# TC37XPD register map
Vendor: Infineon; Series: ATVMC; File version: 100
CPU: other r0p0, little endian, MPU, FPU, vendor SysTick, 4 interrupt priority bits
Registers are 32-bit, read-write, reset 0x0 unless marked. A register's access mark holds for its fields unless they carry their own. Offsets are from the block's base; [hi:lo] are bit positions; {n}, {i} and the like mark numbered series.

## PSI5S
Base 0xF0007000
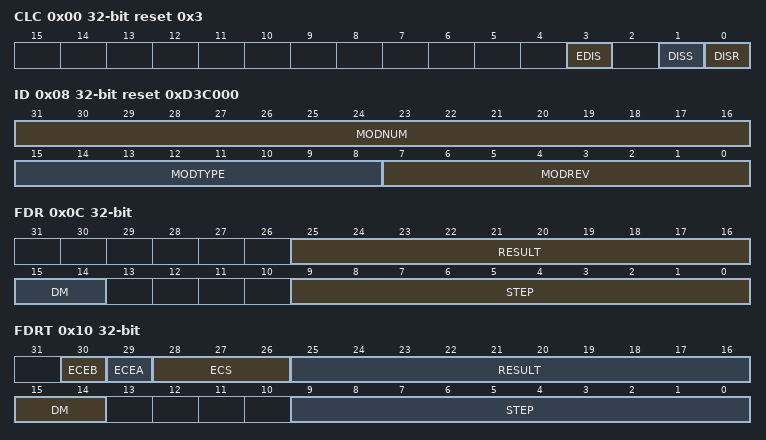
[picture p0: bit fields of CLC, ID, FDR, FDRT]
0x00 CLC access per field reset 0x3 — Clock Control Register resetvalue={Application Reset:0x3}
  [3] EDIS rw — External Sleep Mode Request Disable Bit EDIS. Used to control module s sleep mode. If this bit is cleared the kernel clocks f PSI5 S and the ASC clock f ASC are disabled during System Sleep Mode.
  [1] DISS ro — Module Disable Status Bit DISS. Bit indicates the current status of the module.
  [0] DISR rw — Module Disable Request Bit DISR. Used for enable disable control of the module. This bit disables the kernel clocks f PSI5 S and the ASC clock f ASC .
0x08 ID ro reset 0xD3C000 (reset mask 0xFFFFFF00) — Module Identification Register resetvalue={Application Reset:0x0D3C000}
  [31:16] MODNUM — Module Number Value MODNUM. This bit field defines the module identification number for the PSI5 S 00D3 H
  [15:8] MODTYPE — Module Type MODTYPE. This bit field defines the module as a 32 bit module C0 H
  [7:0] MODREV — Module Revision Number MODREV. This bit field defines the module revision number. The value of a module revision starts with 01 H first revision .
0x0C FDR access per field — PSI5 S Fractional Divider Register resetvalue={Application Reset:0x0}
  [25:16] RESULT ro — Result Value RESULT. Bit field for the addition result.
  [15:14] DM rw — Divider Mode DM. DM selects normal or fractional divider mode.
  [9:0] STEP rw — Step Value STEP. Reload or addition value for RESULT.
0x10 FDRT access per field — Fractional Divider Register for Time Stamp resetvalue={Application Reset:0x0}
  [30] ECEB rw — External Time Stamp Clear Enable B ECEB. Enables the external trigger line selected by ECS to clear the global Time Stamp Counter TSCNTB.CTS on rising edge of the external trigger.
  [29] ECEA rw — External Time Stamp Clear Enable A ECEA. Enables the external trigger line selected by ECS to clear the global Time Stamp Counter TSCNTA.CTS on rising edge of the external trigger.
  [28:26] ECS rw — External Time Stamp Clear Source Select ECS. Selects the external trigger line that clears the global Time Stamp Counters TSCNTA B.CTS if this is enabled by ECEA ECEB.
  [25:16] RESULT ro — Result Value RESULT. Bit field for the addition result.
  [15:14] DM rw — Divider Mode DM. DM selects normal or fractional divider mode.
  [9:0] STEP rw — Step Value STEP. Reload or addition value for RESULT.
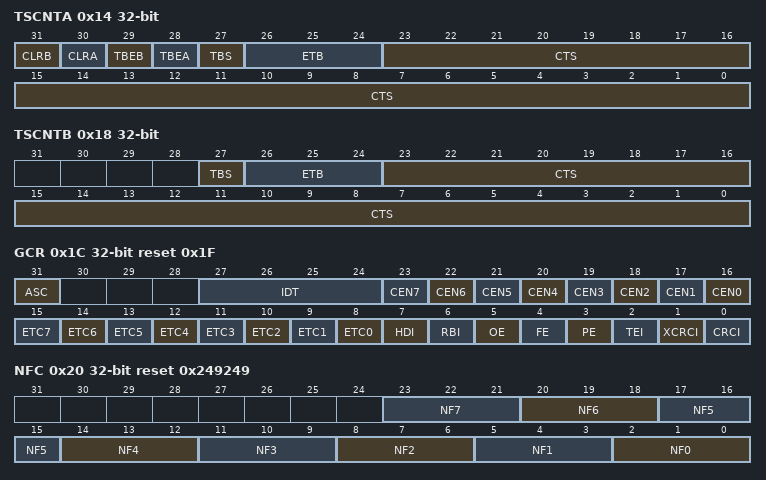
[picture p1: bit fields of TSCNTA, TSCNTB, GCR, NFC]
0x14 TSCNTA access per field — Time Stamp Count Register A resetvalue={Application Reset:0x0}
  [31] CLRB wo — Clear Time Stamp Counter B CLRB. This bit clears TSCNTB.CTS. TSCNTB.CTS counts on starting from 0.
  [30] CLRA wo — Clear Time Stamp Counter A CLRA. This bit clears TSCNTA.CTS. TSCNTA.CTS counts on starting from 0.
  [29] TBEB rw — Time Base Enable TSCNTB TBEB. This bit starts stops TSCNTB.CTS
  [28] TBEA rw — Time Base Enable TSCNTA TBEA. This bit starts stops TSCNTA.CTS
  [27] TBS rw — Time Base Select TBS. This bit selects the clock source for CTS
  [26:24] ETB rw — External Time Base Select ETB. Selects the external clock line for counter CTS if TBS is set.
  [23:0] CTS ro — Current Time Stamp for the Module CTS. This bit field shows the current time stamp.
0x18 TSCNTB access per field — Time Stamp Count Register B resetvalue={Application Reset:0x0}
  [27] TBS rw — Time Base Select TBS. This bit selects the clock source for CTS
  [26:24] ETB rw — External Time Base Select ETB. Selects the external clock line for counter CTS.
  [23:0] CTS ro — Current Time Stamp for the Module CTS. This bit field shows the current time stamp.
0x1C GCR reset 0x1F — Global Control Register resetvalue={Application Reset:0x1F}
  [31] ASC — ASC only Mode ASC. is selected if bit is set. The ASC registers are fully controllable by SW via SPB. If cleared the ASC is controlled by the message reassembly unit and the message generation unit. RBUF and TBUF are no longer writable by SW and interrupts are handled by the message reassembly block automatically.
  [27:24] IDT — Idle Time GLOBAL VALUE FOR ALL CHANNELS IDT. determines the number of stop bits in addition to the stop bit of the last UART Frame that is required for SOF detection. IDT 1 idle bit times are allowed tolerated within one Packet Frame. Default is IDT 0 i.e. back to back transfer.
  [n+16] CEN{n} (n=0..7) — Enable Channel 7 CEN7. This bit enables PSI5 S Channel x. If cleared all internal state machines of the receiver and the sender are forced to default idle state while all registers can be read and written. Used for configuration of a channel. Frames received for a disabled channel are copied to ChID 0 FID 1 with original IDs.
  [n+8] ETC{n} (n=0..7) — Enable Channel Trigger Counter CTV7.CTC ETC7. This bit enables CTVx.CTC. The bits ETC0 8230 x can be set with one write access to synchronously start all counters. This is required for proper sync pulse staggering. If set CTCx counts on starting from its current value. CTCx can be written only if ETCx is cleared stopped .
  [7] HDI — HDI HDI. is selected if bit is set.
  [6] RBI — RBI RBI. is selected if bit is set.
  [5] OE — OE OE. is selected if bit is set.
  [4] FE — FE FE. is selected if bit is set.
  [3] PE — PE PE. is selected if bit is set.
  [2] TEI — TEI TEI. is selected if bit is set.
  [1] XCRCI — XCRCI XCRCI. is selected if bit is set.
  [0] CRCI — CRCI CRCI. is selected if bit is set.
0x20 NFC reset 0x249249 — Number of Frames Control Register resetvalue={Application Reset:0x249249}
  [3n+2:3n] NF{n} (n=0..7) — Number of expected Frames on Channel 7 NF7
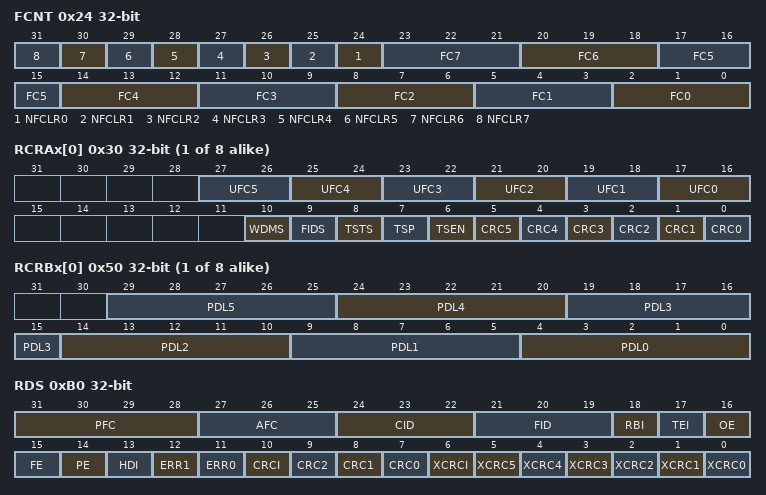
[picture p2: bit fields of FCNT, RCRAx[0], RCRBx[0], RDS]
0x24 FCNT access per field — Frame Counter Register resetvalue={Application Reset:0x0}
  [n+24] NFCLR{n} wo (n=0..7) — Clear Number of Frame Counter for Channel 7 NFCLR7. Clears the referring counter FCNT.FCx. Intended for use during recovery from TEI. If set while a frame is being received this action results in FCx 1 . Thus FCx will never be 0 when RDI RSI signal a new receive frame. Use with care
  [3n+2:3n] FC{n} ro (n=0..7) — Frame Counter for Channel 7 FC7. Contains the number of received frames on Channel 160 x. Copied to RDR.FID if RCRAx.FIDS is set.
0x28 IOCR — Input and Output Control Register resetvalue={Application Reset:0x0}
  [1:0] ALTI — Alternate Input Select ALTI. Selects the alternate input for RX of the ASC
{0x30+4i} RCRAx[{i}] (i=0..7) — Receiver Control Register A0 resetvalue={Application Reset:0x0}
  [2n+17:2n+16] UFC{n} (n=0..5) — UART Frame Count per Packet Frame in Slot 5 UFC5. This bit field defines the number of UART Frames per Packet Frame that are expected for Slot y. This bit field is looked up before potential modification of FID according to FIDS.
  [10] WDMS — Watch Dog Timer Mode Select WDMS
  [9] FIDS — Frame ID Select FIDS
  [8] TSTS — Time Stamp Trigger Select TSTS
  [7] TSP — Time Stamp Select TSP. For non recoverable Packets stored in ChID 0 FID 1 with original IDs TSCNTA is captured in TSM and not in TSCR0 independent from TSP .
  [6] TSEN — Time Stamp Enable TSEN. Enables the time stamping for channel x
  [n] CRC{n} (n=0..5) — CRC or Parit5 Selection CRC5. If set a 3 bit CRC checksum is expected for the PSI5 S channel x in slot y. Else 1 bit Parity is assumed. This bit field is looked up before potential modification of FID according to FIDS.
{0x50+4i} RCRBx[{i}] (i=0..7) — Receiver Control Register B0 resetvalue={Application Reset:0x0}
  [5n+4:5n] PDL{n} (n=0..5) — Payload Data Length PDL5. PDL determines the number of bits in a Packet Frame frame for Slot y. It also determines the position of the CRC Parity bit. E.g. 8 defines 8 data bits on position 7 0 . On bit position 8 the CRC Parity is located. See CROSSREFERENCE . If PDLy is cleared 8216 0 8217 no frame is expected for this slot. Packet Frames received for a slot with PDL 8216 0 8217 are copied to ChID 0 FID 1 with original IDs without further processing. This bit field is looked up before potential modification of FID according to RCRAx.FIDS
{0x70+4i} WDTx[{i}] (i=0..7) — Watch Dog Timer Register 0 resetvalue={Application Reset:0x0}
  [23:0] WDL — Watch Dog Timer Limit WDL. for channel x. If no watch dog is needed WDL is cleared the internal watch dog timer is stopped and no check is performed. CENx must be clear for write access.
{0x90+4i} TSCRx[{i}] (i=0..7) ro — Capture Register TSCR0 resetvalue={Application Reset:0x0}
  [23:0] TS — Time Stamp TS. of the last sync pulse sent for channel x.
0xB0 RDS ro — Receive Status Register resetvalue={Application Reset:0x0}
  [31:28] PFC — Packet Frame Count PFC. For data consistency RDR RDS and TSM are tagged with a Packet Frame count value. For each channel there is a separate internal packet counter. This allows to read a triplet of RDR RDS and TSM from the system memory without looking at interrupts. If the PFC is identical all three values belong together. Otherwise they need to be read again until PFC is identical.
  [27:25] AFC — Actual UART Frame Count AFC. This bit field shows the number of UART frames actually received. This is used to further analyze non recoverable frames by SW or during debugging.
  [24:22] CID — Channel ID Channel Number CID
  [21:19] FID — Frame ID Frame Number FID. See bit RCRAx.FIDS for actual content.
  [18] RBI — Receive Buffer Overflow Flag RBI. This bit is set after a frame has been received while the old one was not read from RDR. I.e. the kernel wants to set interrupt RDI and finds RDI already set. The old data is overwritten by the new data.
  [17] TEI — Time Error Flag TEI. This bit is set if the watch dog timer expired. Depending from RCRAx.WDMS either the distance between two RDIs is longer than specified in WDL or it expired without reception of CHCI in time. I.e. the time from issuing the sync pulse to reception of the last expected frame configured in NFC.NFx was too long. If WDMS is in synchronous mode all frames after TEI have TEI set in RDS until either CHCI is issued or INSTATx.TEI is cleared by SW. RDS.TEI flag is independently from INTENx.TEI.
  [16] OE — ASC Overrun Error Flag OE. This bit is set if the error flag signaling an overrun error was set during reception of one of the ASC Bytes transporting this PSI5 frame.
  [15] FE — ASC Framing Error Flag FE. This bit is set if the error flag signaling a framing error was set during reception of one of the ASC Bytes transporting this PSI5 frame.
  [14] PE — ASC Parity Error Flag PE. This bit is set if the error flag signalling a parity error was set during reception of one of the ASC Bytes transporting this PSI5 frame.
  [13] HDI — Header Error Signalled Flag HDI. This bit is set if at least one of the error signalling flags in the enveloping Packet Frame Err0 and Err1 is set.
  [12] ERR1 — Error signalling Flag 1 ERR1. This bit represents the status of the error signalling flag Err1 in the enveloping Packet Frame.
  [11] ERR0 — Error signalling Flag 0 ERR0. This bit represents the status of the error signalling flag Err0 in the enveloping Packet Frame.
  [10] CRCI — CRC Error Flag CRCI. This bit is set if the CRC or Parity check on the transported PSI5 frame fails.
  [9] CRC2 — CRC CRC2. of last frame. CRC0 Parity is on bit position 7. If Parity is used CRC1 2 are always 0.
  [8] CRC1 — CRC CRC2. of last frame. CRC0 Parity is on bit position 7. If Parity is used CRC1 2 are always 0.
  [7] CRC0 — CRC CRC2. of last frame. CRC0 Parity is on bit position 7. If Parity is used CRC1 2 are always 0.
  [6] XCRCI — XCRC Error Flag XCRCI. This bit is set if the CRC check on the enveloping Packet Frame fails including the case where XCRC check can not be performed non recoverable frames see CROSSREFERENCE .
  [n] XCRC{n} (n=0..5) — XCRC XCRC5. CRC of last Packet Frame. XCRC0 is on bit position 0.
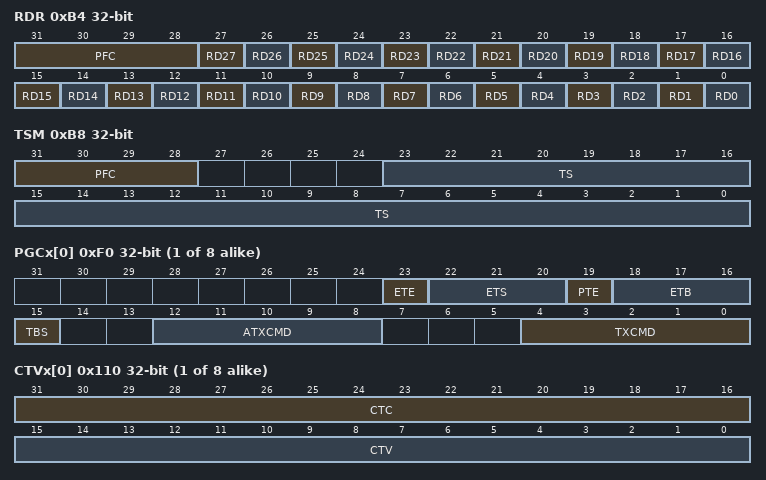
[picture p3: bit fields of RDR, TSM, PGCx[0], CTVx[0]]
0xB4 RDR ro — Receive Data Register resetvalue={Application Reset:0x0}
  [31:28] PFC — Packet Frame Count PFC. For data consistency RDR RDS and TSM are tagged with a Packet Frame count value. For each channel there is a separate internal packet counter. This allows to read a triplet of RDR RDS and TSM from the system memory without looking at interrupts. If the PFC is identical all three values belong together. Otherwise they need to be read again until PFC is identical.
  [n] RD{n} (n=0..27) — PSI5 Receive Data RD27. of last frame. D0 is on bit position 0.
0xB8 TSM ro — Time Stamp Mirror Register resetvalue={Application Reset:0x0}
  [31:28] PFC — Packet Frame Count PFC. For data consistency RDR RDS and TSM are tagged with a Packet Frame count value. For each channel there is a separate internal packet counter. This allows to read a triplet of RDR RDS and TSM from the system memory without looking at interrupts. If the PFC is identical all three values belong together. Otherwise they need to be read again until PFC is identical.
  [23:0] TS — Time Stamp TS. of the last sync pulse sent on channel x.
0xD0 TAR ro — Target Address Register resetvalue={Application Reset:0x0}
  [31:2] TA — Target Address TA. Contains the upper 30 bit of the target address for the next DMA transfer. The 32 bit target address must be word aligned. Thus the 2 LSBs are fixed to 0. It is updated each time a new Packet Frame is received completely.
0xD4 BAR — Base Address Register resetvalue={Application Reset:0x0}
  [31:2] BA — Base Address BA. Contains the upper 30 bits of the base address for the DMA transfers. The 32 bit base address must be word aligned. Thus the 2 LSBs are fixed to 0.
{0xF0+4i} PGCx[{i}] (i=0..7) — Pulse Generation Control Register 0 resetvalue={Application Reset:0x0}
  [23] ETE — External Trigger Enable ETE. Angle sync. trigger external line is selected by ETS. Should be 0 if PTE is set.
  [22:20] ETS — External Trigger Select ETS. Selects the external trigger line for pulse generation e.g. angle synchronous .
  [19] PTE — Periodic Trigger Enable PTE. Periodic trigger is defined by CTVx. Should be 0 if ETE is set.
  [18:16] ETB — External Time Base Select ETB. Selects the external clock line for counter CTVx.
  [15] TBS — Time Base Select TBS. This bit selects the clock source for CTVx
  [12:8] ATXCMD — Alternate TX Command ATXCMD. Defines the value that is copied to the ASC FIFO for the alternate pulse width i.e. for coding a 1 .
  [4:0] TXCMD — TX Command TXCMD. Defines the value that is copied to the ASC FIFO for coding a 0 .
{0x110+4i} CTVx[{i}] (i=0..7) — Channel Trigger Value Register 0 resetvalue={Application Reset:0x0}
  [31:16] CTC — Channel Trigger Counter CTC. This bit field allows to read the current counter value of the reset timer cell CTVx. If GCR.ETCx is cleared CTC can be written.
  [15:0] CTV — Channel Trigger Value CTV CTV. Contains the compare value exact match of Channel Trigger CTC at which a sync pulse is triggered for channel x and the counter CTC is cleared. If cleared CTC is stopped and no pulse triggered.
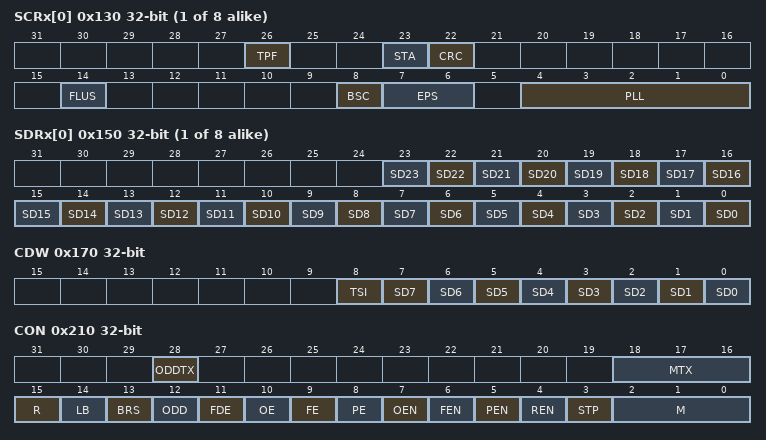
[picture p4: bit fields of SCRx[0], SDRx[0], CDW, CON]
{0x130+4i} SCRx[{i}] (i=0..7) access per field — Send Control Register 0 resetvalue={Application Reset:0x0}
  [26] TPF ro — Transmit in Progress Flag TPF. If set data preparation and transmission is in progress start sequence or CRC or stuffing bits or data from SDRx are being transferred. It is cleared automatically after preparation and transmitting is finished. It gets set by HW immediately with the write access to SDRx and cleared by HW when the last pulse request is issued to the message generator usually a CRC bit from the CRC Generator If set write access to SDRx will not change any data and issue TPOI.
  [23] STA rw — Start Sequence Generation Control STA
  [22] CRC rw — CRC Generation Control CRC
  [14] FLUS wo — Flush SDRx FLUS. Setting this bit stops shifting out the data in SDRx the start sequence or CRC if any and clears the referring FSMs and counters if EPS 0 0 SDRx is flushed by setting all bits if EPS 0 1 SDRx is flushed by clearing all bits clears TPF TPIx is issued at the end of successful flushing. Reads always as zero.
  [8] BSC rw — Bit Stuffing Control BSC. Depending from bit EPS 1 after 3 bits a 1 is inserted Frame Format 1 3 or after 6 bits a 0 is inserted Frame Format 4
  [7:6] EPS rw — Enhanced Protocol Selection EPS. EPS 0 controls the Bit Format and MSB Fill bit. 0 Tooth Gap MSB Fill 1 1 PWM MSB Fill 0 EPS 1 controls the Frame Format 0 Frame Format 1 3 1 Frame Format 4
  [4:0] PLL rw — Pay Load Length of Registers SDRx PLL. Defines the length that is taken into account. PLL needs to written before SDRx is used for proper operation.
{0x150+4i} SDRx[{i}] (i=0..7) — Send Data Register 0 resetvalue={Application Reset:0x0}
  [n] SD{n} (n=0..23) — SD23 SD23. Send data of next ECU to Sensor frame. Each time a bit is shifted out the whole content is shifted right by 1 position and the MSB is filled with 1 or 0 depending from EPS 0 . This allows to read back SDR and determine the status of the shift process by SW. The unused MSBs bit position SCRx.PLL and higher must be written with 0 if EPS 0 is set PWM Method and with 1 if EPS 0 is cleared Tooth Gap Method . This is required as the respective standard value is shifted into the register from MSB during shift out operation. SDRx will be filled with this value after shift out process.
0x170 CDW — CPU Direct Write Register resetvalue={Application Reset:0x0}
  [8] TSI — Trigger Pulse Indicator TSI. If this bit is set a sync pulse is assumed and thus a time stamp is captured when the command leaves the FIFO and is written to ASC TX Register. Bits SD 7 5 select the channel for which the time stamp is captured. RCRAx.TSTS must be cleared. If set the time stamp is captured on Packet Frame reception only.
  [n] SD{n} (n=0..7) — SD7 SD7. Send data of next ECU to Sensor frame.
0x210 CON access per field — Control Register resetvalue={Application Reset:0x0}
  [28] ODDTX rw — Parity Selection TX direction ODDTX. While bit field ODD controls the RX path ODDTX controls the mode for the TX path.
  [18:16] MTX rw — Mode Selection TX direction MTX. While bit field M controls the RX path MTX controls the mode for the TX path.
  [15] R rw — Baud Rate Generator Run Control R. Register BG should only be written if R 0.
  [14] LB rw — Loop back Mode Enable LB
  [13] BRS rw — Baud Rate Selection BRS. BRS is don t care if FDE 1 fractional divider enabled FDE is don t care and assumed 0 in Synchr. Mode.
  [12] ODD rw — Parity Selection ODD
  [11] FDE rw — Fractional Divider Enable FDE. FDE is don t care and assumed 0 in Synchr. Mode.
  [10] OE ro — ASC Overrun Error Flag OE. Set by hardware on an overrun error OEN 1 . Must be reset by software.
  [9] FE ro — ASC Framing Error Flag FE. Set by hardware on a framing error FEN 1 . Must be reset by software.
  [8] PE ro — ASC Parity Error Flag PE. Set by hardware on a parity error PEN 1 . Must be reset by software.
  [7] OEN rw — Overrun Check Enable OEN
  [6] FEN rw — Framing Check Enable asynchronous mode only FEN
  [5] PEN rw — Parity Check Enable asynchronous mode only PEN
  [4] REN ro — Receiver Enable Control REN. Bit is reset by hardware after reception of a Byte in Synchronous Mode.
  [3] STP rw — Number of Stop Bit Selection STP
  [2:0] M rw — Mode Selection M
0x214 BG — Baud Rate Timer Reload Register resetvalue={Application Reset:0x0}
  [12:0] BR_VALUE — Baud Rate Timer Reload Register Value BR VALUE. Reading BR VALUE returns the 13 bit content of the baud rate timer. Writing BR VALUE loads the baud rate timer reload register. BG should only be written if CON.R 0.
0x218 FDV — Fractional Divider Register resetvalue={Application Reset:0x0}
  [10:0] FD_VALUE — Fractional Divider Register Value FD VALUE. FD VALUE contains the 11 bit value n of the fractional divider which determines the fractional divider ratio n 2048 n 0 2047 . With n 0 the fractional divider is switched off divider ratio 1 .
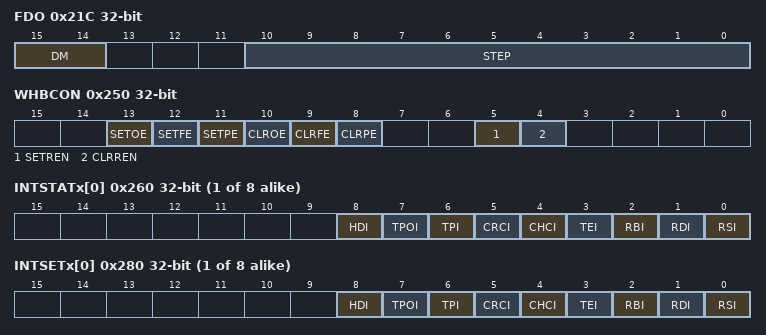
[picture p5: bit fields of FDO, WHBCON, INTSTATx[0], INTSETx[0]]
0x21C FDO — Fractional Divider for Output CLK Register resetvalue={Application Reset:0x0}
  [15:14] DM — Divider Mode DM. DM selects normal or fractional divider mode.
  [10:0] STEP — Step Value STEP. Reload or addition value for internal accumulator.
0x220 TBUF — Transmit Buffer Register resetvalue={Application Reset:0x0}
  [8:0] TD_VALUE — Transmit Data Register Value TD VALUE. TBUF contains the data to be transmitted in the asynchronous and synchronous operating modes of the ASC. Data transmission is double buffered therefore a new value can be written to TBUF before the transmission of the previous value is complete.
0x224 RBUF ro — Receive Buffer Register resetvalue={Application Reset:0x0}
  [8:0] RD_VALUE — Receive Data Register Value RD VALUE. RBUF contains the received data bits and depending on the selected mode the parity bit in the asynchronous and synchronous operating modes of the ASC. In Asynchronous Mode with CON.M 011 B 7 bit data parity the received parity bit is written into RBUF.7. In Asynchronous Mode with CON.M 111 B 8 bit data parity the received parity bit is written into RBUF.8.
0x250 WHBCON wo — Write Hardware Bits Control Register resetvalue={Application Reset:0x0}
  [13] SETOE — Set Overrun Error Flag SETOE. Bit is always read as 0.
  [12] SETFE — Set Framing Error Flag SETFE. Bit is always read as 0.
  [11] SETPE — Set Parity Error Flag SETPE. Bit is always read as 0.
  [10] CLROE — Clear Overrun Error Flag CLROE. Bit is always read as 0.
  [9] CLRFE — Clear Framing Error Flag CLRFE. Bit is always read as 0.
  [8] CLRPE — Clear Parity Error Flag CLRPE. Bit is always read as 0.
  [5] SETREN — Set Receiver Enable Bit SETREN. Bit is always read as 0.
  [4] CLRREN — Clear Receiver Enable Bit CLRREN. Bit is always read as 0.
{0x260+4i} INTSTATx[{i}] (i=0..7) ro — Interrupt Status Register 0 resetvalue={Application Reset:0x0}
  [8] HDI — Header Error Signalled Flag HDI. This bit is set if at least one of the error signalling flags in the enveloping Packet Frame Err0 and Err1 is set. Up
  [7] TPOI — Transmit Preparation Overflow Interrupt Request Flag TPOI. This bit is set if SDR is written while TPF is set. The old data is NOT overwritten. This bit can be cleared by bit INTCLRx.TPOI. This bit can be set by bit INTSETx.TPOI. This bit is set independently from INTENx.
  [6] TPI — Transfer Preparation Interrupt Request Flag TPI. This bit is set after data to be transferred has been moved completely. Thus a new value can be written to SDRx. This bit can be cleared by bit INTCLRx.TPI. This bit can be set by bit INTSETx.TPI. This bit is set independently from INTENx.
  [5] CRCI — CRC Error Request Flag CRCI. This bit is set if the CRC fails. This bit can be cleared by bit INTCLRx.CRCI. This bit can be set by bit INTSETx.CRCI. This bit is set independently from INTENx.
  [4] CHCI — Channel Completed Interrupt Request Flag CHCI. This bit is set if FCNT.FCx equals NFC.NFx. This bit can be cleared by bit INTCLRx.CHCI. This bit can be set by bit INTSETx.CHCI. This bit is set independently from INTENx.
  [3] TEI — Timing Error Interrupt Request Flag TEI. This bit is set if the watch dog timer expired. Depending from RCRAx.WDMS either the distance between two RDIs is longer than specified in WDL or it expired without reception of CHCI in time. I.e. the time from issuing the sync pulse to reception of the last expected frame configured in NFC.NFx was too long. Note that the root cause might be a non recoverable frame This bit can be cleared by bit INTCLRx.TEI. This bit can be set by bit INTSETx.TEI. This bit is set independently from INTENx.
  [2] RBI — Receive Buffer Overflow Interrupt Request Flag RBI. This bit is set after a frame has been received while the old one was not read from RDR. I.e. the kernel wants to set interrupt RDI and finds this interrupt already set. The old data is overwritten by the new data. This bit is NOT cleared by reading RDR. This bit can be cleared by bit INTCLRx.RBI. This bit can be set by bit INTSETx.RBI. This bit is set independently from INTENx.
  [1] RDI — Receive Data Interrupt Request Flag RDI. RDI is activated when a received frame is moved to a Receive Data Register RDR. Both RDI and RSI will be issued together at correct reception. This bit can be cleared by bit INTCLRx.RDI. This bit can be set by bit INTSETx.RDI. This bit is set independently from INTENx.
  [0] RSI — Receive Success Interrupt Request Flag RSI. This bit is set at the successfully received end of a frame. It indicates that this frame is free of the errors CRCI XCRCI TEI PE FE OE RBI HDI if selected to be taken into account in register GCR. This bit can be cleared by bit INTCLRx.RSI. This bit can be set by bit INTSETx.RSI. This bit is set independently from INTENx.
{0x280+4i} INTSETx[{i}] (i=0..7) wo — Interrupt Set Register 0 resetvalue={Application Reset:0x0}
  [8] HDI — Set Interrupt Request Flag HDI HDI. Setting this bit set bit INTSTATx.HDI. Clearing this bit has no effect. Reading this bit returns always zero.
  [7] TPOI — Set Interrupt Request Flag TPOI TPOI. Setting this bit set bit INTSTATx.TPOI. Clearing this bit has no effect. Reading this bit returns always zero.
  [6] TPI — Set Interrupt Request Flag TPI TPI. Setting this bit set bit INTSTATx.TPI. Clearing this bit has no effect. Reading this bit returns always zero.
  [5] CRCI — Set Interrupt Request Flag CRCI CRCI. Setting this bit set bit INTSTATx.CRCI. Clearing this bit has no effect. Reading this bit returns always zero.
  [4] CHCI — Set Interrupt Request Flag CHCI CHCI. Setting this bit set bit INTSTATx.CHCI. Clearing this bit has no effect. Reading this bit returns always zero.
  [3] TEI — Set Interrupt Request Flag TEI TEI. Setting this bit set bit INTSTATx.TEI. Clearing this bit has no effect. Reading this bit returns always zero.
  [2] RBI — Set Interrupt Request Flag RBI RBI. Setting this bit set bit INTSTATx.RBI. Clearing this bit has no effect. Reading this bit returns always zero.
  [1] RDI — Set Interrupt Request Flag RDI RDI. Setting this bit set bit INTSTATx.RDI. Clearing this bit has no effect. Reading this bit returns always zero.
  [0] RSI — Set Interrupt Request Flag RSI RSI. Setting this bit set bit INTSTATx.RSI. Clearing this bit has no effect. Reading this bit returns always zero.
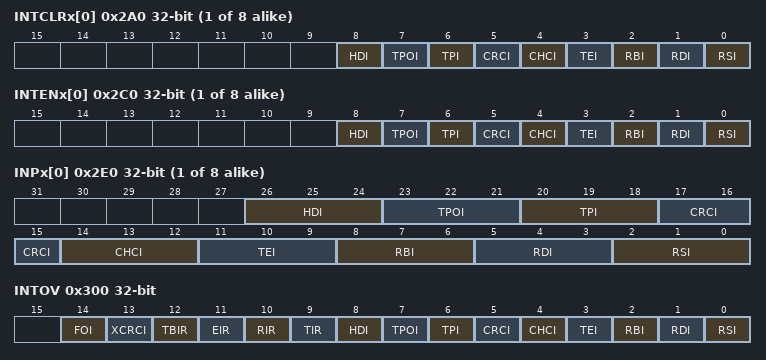
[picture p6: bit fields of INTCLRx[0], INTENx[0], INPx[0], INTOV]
{0x2A0+4i} INTCLRx[{i}] (i=0..7) wo — Interrupt Clear Register 0 resetvalue={Application Reset:0x0}
  [8] HDI — Clear Interrupt Request Flag HDI HDI. Setting this bit clears bit INTSTATx.HDI. Clearing this bit has no effect. Reading this bit returns always zero.
  [7] TPOI — Clear Interrupt Request Flag TPOI TPOI. Setting this bit clears bit INTSTATx.TPOI. Clearing this bit has no effect. Reading this bit returns always zero.
  [6] TPI — Clear Interrupt Request Flag TPI TPI. Setting this bit clears bit INTSTATx.TPI. Clearing this bit has no effect. Reading this bit returns always zero.
  [5] CRCI — Clear Interrupt Request Flag CRCI CRCI. Setting this bit clears bit INTSTATx.CRCI. Clearing this bit has no effect. Reading this bit returns always zero.
  [4] CHCI — Clear Interrupt Request Flag CHCI CHCI. Setting this bit clears bit INTSTATx.CHCI. Clearing this bit has no effect. Reading this bit returns always zero.
  [3] TEI — Clear Interrupt Request Flag TEI TEI. Setting this bit clears bit INTSTATx.TEI. Clearing this bit has no effect. Reading this bit returns always zero.
  [2] RBI — Clear Interrupt Request Flag RBI RBI. Setting this bit clears bit INTSTATx.RBI. Clearing this bit has no effect. Reading this bit returns always zero.
  [1] RDI — Clear Interrupt Request Flag RDI RDI. Setting this bit clears bit INTSTATx.RDI. Clearing this bit has no effect. Reading this bit returns always zero.
  [0] RSI — Clear Interrupt Request Flag RSI RSI. Setting this bit clears bit INTSTATx.RSI. Clearing this bit has no effect. Reading this bit returns always zero.
{0x2C0+4i} INTENx[{i}] (i=0..7) — Interrupt Enable Register 0 resetvalue={Application Reset:0x0}
  [8] HDI — Enable Interrupt Request HDI HDI
  [7] TPOI — Enable Interrupt Request TPOI TPOI
  [6] TPI — Enable Interrupt Request TPI TPI
  [5] CRCI — Enable Interrupt Request CRCI CRCI
  [4] CHCI — Enable Interrupt Request CHCI CHCI
  [3] TEI — Enable Interrupt Request TEI TEI
  [2] RBI — Enable Interrupt Request RBI RBI
  [1] RDI — Enable Interrupt Request RDI RDI
  [0] RSI — Enable Interrupt Request RSI RSI
{0x2E0+4i} INPx[{i}] (i=0..7) — Interrupt Node Pointer Register 0 resetvalue={Application Reset:0x0}
  [26:24] HDI — Interrupt Node Pointer for HDI HDI. This bit field defines the interrupt node that is requested due to the set condition for bit INTSTATx.HDI. For bit field definition see RSI.
  [23:21] TPOI — Interrupt Node Pointer for TPOI TPOI. This bit field defines the interrupt node that is requested due to the set condition for bit INTSTATx.TPOI. For bit field definition see RSI.
  [20:18] TPI — Interrupt Node Pointer for Interrupt TOI TPI. This bit field defines the interrupt node that is requested due to the set condition for bit INTSTATx.TPI if enabled by bit INTENx.TPI . For bit field definition see RSI.
  [17:15] CRCI — Interrupt Node Pointer for Interrupt CRCI CRCI. This bit field defines the interrupt node that is requested due to the set condition for bit INTSTATx.CRCI. For bit field definition see RSI.
  [14:12] CHCI — Interrupt Node Pointer for Interrupt CHCI CHCI. This bit field defines the interrupt node that is requested due to the set condition for bit INTSTATx.CHCI if enabled by bit INTENx.CHCI . For bit field definition see RSI.
  [11:9] TEI — Interrupt Node Pointer for Interrupt TEI TEI. This bit field defines the interrupt node that is requested due to the set condition for bit INTSTATx.TEI if enabled by bit INTENx.TEI . For bit field definition see RSI.
  [8:6] RBI — Interrupt Node Pointer for Interrupt RBI RBI. This bit field defines the interrupt node that is requested due to the set condition for bit INTSTATx.RBI if enabled by bit INTENx.RBI . For bit field definition see RSI.
  [5:3] RDI — Interrupt Node Pointer for Interrupt RDI RDI. This bit field defines the interrupt node that is requested due to the set condition for bit INTSTATx.RDI if enabled by bit INTENx.RDI . For bit field definition see RSI.
  [2:0] RSI — Interrupt Node Pointer for Interrupt RSI RSI. This bit field defines the interrupt node that is requested due to the set condition for bit INTSTATx.RSI if enabled by bit INTENx.RSI .
0x300 INTOV ro — Interrupt Overview Register resetvalue={Application Reset:0x0}
  [14] FOI — Interrupt Pending on Node Pointer FOI FOI. See details of INTOV.TIR.
  [13] XCRCI — Interrupt Pending on Node Pointer XCRCI XCRCI. See details of INTOV.TIR.
  [12] TBIR — Interrupt Pending on Node Pointer TBIR TBIR. See details of INTOV.TIR.
  [11] EIR — Interrupt Pending on Node Pointer EIR EIR. See details of INTOV.TIR.
  [10] RIR — Interrupt Pending on Node Pointer RIR RIR. See details of INTOV.TIR.
  [9] TIR — Interrupt Pending on Node Pointer TIR TIR. If any interrupt requested flag is set for this Node Pointer in register INTSTATG AND the referring interrupt is enabled in INTENG then this bit is set. It is automatically reset if all flags in INTSTATG are cleared for which the referring interrupt is enabled in INTENG.
  [8] HDI — Interrupt Pending on Node Pointer HDI HDI. See details of INTOV.HDI.
  [7] TPOI — Interrupt Pending on Node Pointer TPOI TPOI. See details of INTOV.RSI.
  [6] TPI — Interrupt Pending on Node Pointer TPI TPI. See details of INTOV.RSI.
  [5] CRCI — Interrupt Pending on Node Pointer CRCI CRCI. See details of INTOV.RSI.
  [4] CHCI — Interrupt Pending on Node Pointer CHCI CHCI. See details of INTOV.RSI.
  [3] TEI — Interrupt Pending on Node Pointer TEI TEI. See details of INTOV.RSI.
  [2] RBI — Interrupt Pending on Node Pointer RBI RBI. See details of INTOV.RSI.
  [1] RDI — Interrupt Pending on Node Pointer RDI RDI. See details of INTOV.RSI.
  [0] RSI — Interrupt Pending on Node Pointer RSI RSI. If any interrupt requested flag is set for this Node Pointer in register INTSTATx or INTSTATG AND the referring interrupt is enabled in INTENx or INTENG then this bit is set. It is automatically reset if all flags in INTSTATx G are cleared for which the referring interrupt is enabled in INTENx G.
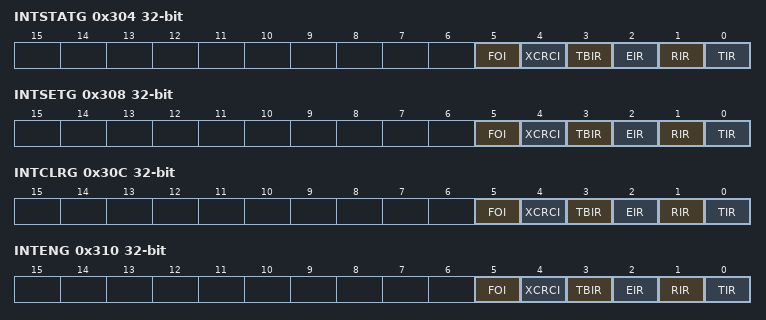
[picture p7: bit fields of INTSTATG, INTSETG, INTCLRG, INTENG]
0x304 INTSTATG ro — Interrupt Status Register Global resetvalue={Application Reset:0x0}
  [5] FOI — FIFO Error Request Flag FOI. This bit is set if the Transmit FIFO of the message generation is overrun i.e. a transfer to the FIFO was generated by the message generation unit or by CDW CPU direct write register while the FIFO was already full. This bit can be cleared by bit INTCLRG.FOI. This bit can be set by bit INTSETG.FOI. This bit is set independently from INTENG.
  [4] XCRCI — XCRC Error Request Flag XCRCI. This bit is set if the CRC check on the enveloping Packet Frame fails including the case where XCRC check can not be performed non recoverable frames see CROSSREFERENCE .The received data is not reliable and stored in ChID 0 FID 1 with original IDs. This bit can be cleared by bit INTCLRG.XCRCI. This bit can be set by bit INTSETG.XCRCI. This bit is set independently from INTENG.
  [3] TBIR — Transmit Buffer Interrupt Request Flag TBIR. This bit can be cleared by bit INTCLRG.TBIR. This bit can be set by bit INTSETG.TBIR. This bit is set independently from INTENG.
  [2] EIR — Error Interrupt Request Flag EIR. The cause of an error interrupt request EIR framing parity overrun error can be identified by the error status flags CON.FE CON.PE and CON.OE This bit can be cleared by bit INTCLRG.EIR. This bit can be set by bit INTSETG.EIR. This bit is set independently from INTENG.
  [1] RIR — Receive Interrupt Request Flag RIR. This bit can be cleared by bit INTCLRG.RIR. This bit can be set by bit INTSETG.RIR. This bit is set independently from INTENG.
  [0] TIR — Transmit Interrupt Request Flag TIR. This bit can be cleared by bit INTCLRG.TIR. This bit can be set by bit INTSETG.TIR. This bit is set independently from INTENG.
0x308 INTSETG wo — Interrupt Set Register Global resetvalue={Application Reset:0x0}
  [5] FOI — Set Interrupt Request Flag FOI FOI. Setting this bit set bit INTSTATG.FOI. Clearing this bit has no effect. Reading this bit returns always zero.
  [4] XCRCI — Set Interrupt Request Flag XCRCI XCRCI. Setting this bit set bit INTSTATG.XCRCI. Clearing this bit has no effect. Reading this bit returns always zero.
  [3] TBIR — Set Interrupt Request Flag TBIR TBIR. Setting this bit set bit INTSTATG.TBIR. Clearing this bit has no effect. Reading this bit returns always zero.
  [2] EIR — Set Interrupt Request Flag EIR EIR. Setting this bit set bit INTSTATG.EIR. Clearing this bit has no effect. Reading this bit returns always zero.
  [1] RIR — Set Interrupt Request Flag RIR RIR. Setting this bit set bit INTSTATG.RIR. Clearing this bit has no effect. Reading this bit returns always zero.
  [0] TIR — Set Interrupt Request Flag TIR TIR. Setting this bit set bit INTSTATG.TIR. Clearing this bit has no effect. Reading this bit returns always zero.
0x30C INTCLRG wo — Interrupt Clear Register Global resetvalue={Application Reset:0x0}
  [5] FOI — Clear Interrupt Request Flag FOI FOI. Setting this bit clears bit INTSTATG.FOI. Clearing this bit has no effect. Reading this bit returns always zero.
  [4] XCRCI — Clear Interrupt Request Flag XCRCI XCRCI. Setting this bit clears bit INTSTATG.XCRCI. Clearing this bit has no effect. Reading this bit returns always zero.
  [3] TBIR — Clear Interrupt Request Flag TBIR TBIR. Setting this bit clears bit INTSTATG.TBIR. Clearing this bit has no effect. Reading this bit returns always zero.
  [2] EIR — Clear Interrupt Request Flag EIR EIR. Setting this bit clears bit INTSTATG.EIR. Clearing this bit has no effect. Reading this bit returns always zero.
  [1] RIR — Clear Interrupt Request Flag RIR RIR. Setting this bit clears bit INTSTATG.RIR. Clearing this bit has no effect. Reading this bit returns always zero.
  [0] TIR — Clear Interrupt Request Flag TIR TIR. Setting this bit clears bit INTSTATG.TIR. Clearing this bit has no effect. Reading this bit returns always zero.
0x310 INTENG — Interrupt Enable Register Global resetvalue={Application Reset:0x0}
  [5] FOI — Enable Interrupt Request FOI FOI
  [4] XCRCI — Enable Interrupt Request XCRCI XCRCI
  [3] TBIR — Enable Interrupt Request TBIR TBIR
  [2] EIR — Enable Interrupt Request EIR EIR
  [1] RIR — Enable Interrupt Request RIR RIR
  [0] TIR — Enable Interrupt Request TIR TIR
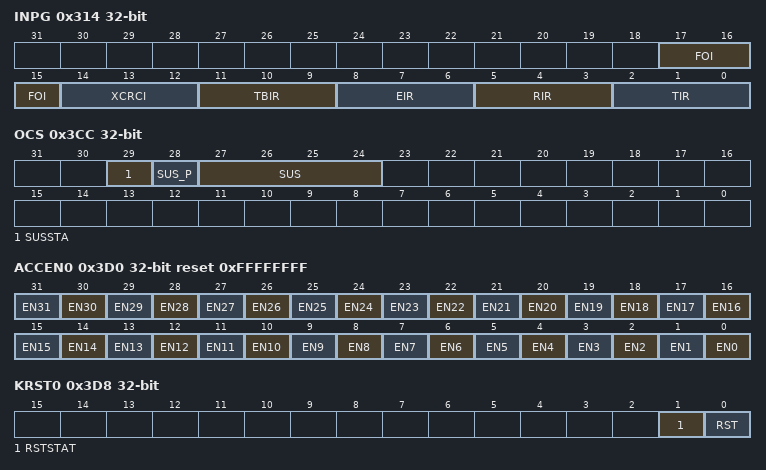
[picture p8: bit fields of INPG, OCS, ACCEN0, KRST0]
0x314 INPG — Interrupt Node Pointer Register Global resetvalue={Application Reset:0x0}
  [17:15] FOI — Interrupt Node Pointer for Interrupt FOI FOI. This bit field defines the interrupt node that is requested due to the set condition for bit INTSTATG.FOI if enabled by bit INTENG.FOI . For bit field definition see TIR.
  [14:12] XCRCI — Interrupt Node Pointer for Interrupt XCRCI XCRCI. This bit field defines the interrupt node that is requested due to the set condition for bit INTSTATG.XCRCI if enabled by bit INTENG.XCRCI . For bit field definition see TIR.
  [11:9] TBIR — Interrupt Node Pointer for Interrupt TBIR TBIR. This bit field defines the interrupt node that is requested due to the set condition for bit INTSTATG.TBIR if enabled by bit INTENG.TBIR . For bit field definition see TIR.
  [8:6] EIR — Interrupt Node Pointer for Interrupt EIR EIR. This bit field defines the interrupt node that is requested due to the set condition for bit INTSTATG.EIR if enabled by bit INTENG.EIR . For bit field definition see TIR.
  [5:3] RIR — Interrupt Node Pointer for Interrupt RIR RIR. This bit field defines the interrupt node that is requested due to the set condition for bit INTSTATG.RIR if enabled by bit INTENG.RIR . For bit field definition see TIR.
  [2:0] TIR — Interrupt Node Pointer for Interrupt TIR TIR. This bit field defines the interrupt node that is requested due to the set condition for bit INTSTATG.TIR if enabled by bit INTENG.TIR .
0x3CC OCS access per field — OCDS Control and Status resetvalue={Debug Reset:0x0}
  [29] SUSSTA ro — Suspend State SUSSTA
  [28] SUS_P wo — SUS Write Protection SUS P. SUS is only written when SUS P is 1 otherwise unchanged. Read as 0.
  [27:24] SUS rw — OCDS Suspend Control SUS. Controls the sensitivity to the suspend signal coming from the OCDS Trigger Switch OTGS Suspend disables the kernel clocks f PSI5 S and the ASC clock f ASC .
0x3D0 ACCEN0 reset 0xFFFFFFFF — Access Enable Register 0 resetvalue={Application Reset:0x0FFFFFFFF}
  [n] EN{n} (n=0..31) — Access Enable for Master TAG ID 31 EN31. This bit enables write access to the module kernel addresses for transactions with the Master TAG ID n
0x3D8 KRST0 access per field — Kernel Reset Register 0 resetvalue={Application Reset:0x0}
  [1] RSTSTAT ro — Kernel Reset Status RSTSTAT. This bit indicates wether a kernel reset was executed or not. This bit is set by the BPI FPI after the execution of a kernel reset in the same clock cycle both reset bits. This bit can be cleared by writing with 1 to the CLR bit in the related KRSTCLR register.
  [0] RST rw — Kernel Reset RST. This reset bit can be used to request for a kernel reset. The kernel reset will be executed if the reset bits of both kernel registers are set. The RST bit will be cleared re set to 0 by the BPI FPI after the kernel reset was executed.
0x3DC KRST1 — Kernel Reset Register 1 resetvalue={Application Reset:0x0}
  [0] RST — Kernel Reset RST. This reset bit can be used to request for a kernel reset. The kernel reset will be executed if the reset bits of both kernel reset registers is set. The RST bit will be cleared re set to 0 by the BPI FPI after the kernel reset was executed.
0x3E0 KRSTCLR wo — Kernel Reset Status Clear Register resetvalue={Application Reset:0x0}
  [0] CLR — Kernel Reset Status Clear CLR. Read always as 0.
